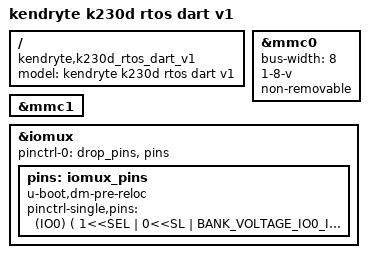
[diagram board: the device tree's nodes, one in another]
/dts-v1/;
#include <dt-bindings/pinctrl/k230-pinctrl.h>
#define BANK_VOLTAGE_IO0_IO1  K230_MSC_1V8
#define BANK_VOLTAGE_IO2_IO13 K230_MSC_3V3
#define BANK_VOLTAGE_IO14_IO25  K230_MSC_3V3
#define BANK_VOLTAGE_IO26_IO37  K230_MSC_3V3
#define BANK_VOLTAGE_IO38_IO49  K230_MSC_3V3
#define BANK_VOLTAGE_IO50_IO61  K230_MSC_3V3
#define BANK_VOLTAGE_IO62_IO63  K230_MSC_3V3
#include "k230d.dtsi"

/ {
    model = "kendryte k230d rtos dart v1";
    compatible = "kendryte,k230d_rtos_dart_v1";
};

&mmc0 {
    bus-width = <8>;
    1-8-v;
    non-removable;
    status = "okay";
};

&mmc1 {
    status = "okay";
};

&iomux {
    pinctrl-names = "default";
    pinctrl-0 = <&drop_pins &pins>;
//	Please pay attention to the bank voltage! will damage the chip.
    pins: iomux_pins {
        u-boot,dm-pre-reloc;
        pinctrl-single,pins = <
		(IO0) ( 1<<SEL | 0<<SL | BANK_VOLTAGE_IO0_IO1 <<MSC | 1<<IE | 0<<OE | 0<<PU | 0<<PD | 2<<DS | 1<<ST ) /* BOOT0 */
		(IO1) ( 1<<SEL | 0<<SL | BANK_VOLTAGE_IO0_IO1 <<MSC | 1<<IE | 0<<OE | 0<<PU | 0<<PD | 2<<DS | 1<<ST ) /* BOOT1 */
		(IO2) ( 0<<SEL | 0<<SL | BANK_VOLTAGE_IO2_IO13 <<MSC | 1<<IE | 1<<OE | 0<<PU | 0<<PD | 7<<DS | 1<<ST ) /* SC038HGS TRIG1: held low for free-running capture */
		(IO3) ( 0<<SEL | 0<<SL | BANK_VOLTAGE_IO2_IO13 <<MSC | 1<<IE | 1<<OE | 0<<PU | 0<<PD | 7<<DS | 1<<ST ) /* GPIO3 */
		(IO4) ( 0<<SEL | 0<<SL | BANK_VOLTAGE_IO2_IO13 <<MSC | 1<<IE | 1<<OE | 0<<PU | 0<<PD | 7<<DS | 1<<ST ) /* SC038HGS PWDN: low = off, high = enabled */
		(IO5) ( 0<<SEL | 0<<SL | BANK_VOLTAGE_IO2_IO13 <<MSC | 1<<IE | 1<<OE | 0<<PU | 0<<PD | 7<<DS | 1<<ST ) /* GPIO5 */
		(IO6) ( 0<<SEL | 0<<SL | BANK_VOLTAGE_IO2_IO13 <<MSC | 1<<IE | 1<<OE | 0<<PU | 0<<PD | 7<<DS | 1<<ST ) /* GPIO6 */
		(IO7) ( 1<<SEL | 0<<SL | BANK_VOLTAGE_IO2_IO13 <<MSC | 0<<IE | 1<<OE | 0<<PU | 1<<PD | 7<<DS | 0<<ST ) /* PWM2 */
		(IO8) ( 1<<SEL | 0<<SL | BANK_VOLTAGE_IO2_IO13 <<MSC | 0<<IE | 1<<OE | 0<<PU | 1<<PD | 7<<DS | 0<<ST ) /* PWM3 */
		(IO10) ( 0<<SEL | 0<<SL | BANK_VOLTAGE_IO2_IO13 <<MSC | 1<<IE | 1<<OE | 0<<PU | 0<<PD | 7<<DS | 1<<ST ) /* GPIO10 */
		(IO11) ( 3<<SEL | 0<<SL | BANK_VOLTAGE_IO2_IO13 <<MSC | 1<<IE | 1<<OE | 1<<PU | 0<<PD | 7<<DS | 1<<ST ) /* IIC2_SCL */
		(IO12) ( 3<<SEL | 0<<SL | BANK_VOLTAGE_IO2_IO13 <<MSC | 1<<IE | 1<<OE | 1<<PU | 0<<PD | 7<<DS | 1<<ST ) /* IIC2_SDA */
		(IO13) ( 0<<SEL | 0<<SL | BANK_VOLTAGE_IO2_IO13 <<MSC | 0<<IE | 0<<OE | 0<<PU | 0<<PD | 0<<DS | 0<<ST ) /* NC */
		(IO14) ( 3<<SEL | 0<<SL | BANK_VOLTAGE_IO14_IO25 <<MSC | 0<<IE | 1<<OE | 1<<PU | 0<<PD | 7<<DS | 0<<ST ) /* QSPI0_CS0 */
		(IO15) ( 3<<SEL | 0<<SL | BANK_VOLTAGE_IO14_IO25 <<MSC | 0<<IE | 1<<OE | 0<<PU | 0<<PD | 7<<DS | 0<<ST ) /* QSPI0_CLK */
		(IO16) ( 3<<SEL | 0<<SL | BANK_VOLTAGE_IO14_IO25 <<MSC | 0<<IE | 1<<OE | 0<<PU | 0<<PD | 7<<DS | 0<<ST ) /* QSPI0_D0 */
		(IO17) ( 3<<SEL | 0<<SL | BANK_VOLTAGE_IO14_IO25 <<MSC | 1<<IE | 0<<OE | 0<<PU | 0<<PD | 7<<DS | 1<<ST ) /* QSPI0_D1 */
		(IO18) ( 0<<SEL | 0<<SL | BANK_VOLTAGE_IO14_IO25 <<MSC | 1<<IE | 1<<OE | 0<<PU | 0<<PD | 7<<DS | 1<<ST ) /* GPIO18 */
		(IO19) ( 0<<SEL | 0<<SL | BANK_VOLTAGE_IO14_IO25 <<MSC | 1<<IE | 1<<OE | 0<<PU | 0<<PD | 7<<DS | 1<<ST ) /* GPIO19 */
		(IO20) ( 2<<SEL | 0<<SL | BANK_VOLTAGE_IO14_IO25 <<MSC | 0<<IE | 1<<OE | 1<<PU | 0<<PD | 7<<DS | 0<<ST ) /* QSPI1_CS0 */
		(IO21) ( 2<<SEL | 0<<SL | BANK_VOLTAGE_IO14_IO25 <<MSC | 0<<IE | 1<<OE | 0<<PU | 0<<PD | 7<<DS | 0<<ST ) /* QSPI1_CLK */
		(IO22) ( 2<<SEL | 0<<SL | BANK_VOLTAGE_IO14_IO25 <<MSC | 0<<IE | 1<<OE | 0<<PU | 0<<PD | 7<<DS | 0<<ST ) /* QSPI1_D0 */
		(IO23) ( 2<<SEL | 0<<SL | BANK_VOLTAGE_IO14_IO25 <<MSC | 1<<IE | 0<<OE | 0<<PU | 0<<PD | 7<<DS | 1<<ST ) /* QSPI1_D1 */
		(IO24) ( 0<<SEL | 0<<SL | BANK_VOLTAGE_IO14_IO25 <<MSC | 1<<IE | 1<<OE | 0<<PU | 0<<PD | 7<<DS | 1<<ST ) /* GPIO24 */
		(IO25) ( 0<<SEL | 0<<SL | BANK_VOLTAGE_IO14_IO25 <<MSC | 1<<IE | 1<<OE | 0<<PU | 0<<PD | 7<<DS | 1<<ST ) /* GPIO25 */
		(IO26) ( 1<<SEL | 0<<SL | BANK_VOLTAGE_IO26_IO37 <<MSC | 0<<IE | 1<<OE | 0<<PU | 0<<PD | 7<<DS | 0<<ST ) /* MMC1_CLK */
		(IO27) ( 1<<SEL | 0<<SL | BANK_VOLTAGE_IO26_IO37 <<MSC | 1<<IE | 1<<OE | 1<<PU | 0<<PD | 7<<DS | 1<<ST ) /* MMC1_CMD */
		(IO28) ( 1<<SEL | 0<<SL | BANK_VOLTAGE_IO26_IO37 <<MSC | 1<<IE | 1<<OE | 1<<PU | 0<<PD | 7<<DS | 1<<ST ) /* MMC1_D0 */
		(IO29) ( 1<<SEL | 0<<SL | BANK_VOLTAGE_IO26_IO37 <<MSC | 1<<IE | 1<<OE | 1<<PU | 0<<PD | 7<<DS | 1<<ST ) /* MMC1_D1 */
		(IO30) ( 1<<SEL | 0<<SL | BANK_VOLTAGE_IO26_IO37 <<MSC | 1<<IE | 1<<OE | 1<<PU | 0<<PD | 7<<DS | 1<<ST ) /* MMC1_D2 */
		(IO31) ( 1<<SEL | 0<<SL | BANK_VOLTAGE_IO26_IO37 <<MSC | 1<<IE | 1<<OE | 1<<PU | 0<<PD | 7<<DS | 1<<ST ) /* MMC1_D3 */
		(IO32) ( 3<<SEL | 0<<SL | BANK_VOLTAGE_IO26_IO37 <<MSC | 0<<IE | 1<<OE | 0<<PU | 0<<PD | 7<<DS | 0<<ST ) /* UART3_TXD */
		(IO33) ( 3<<SEL | 0<<SL | BANK_VOLTAGE_IO26_IO37 <<MSC | 1<<IE | 0<<OE | 0<<PU | 0<<PD | 7<<DS | 1<<ST ) /* UART3_RXD */
		(IO34) ( 1<<SEL | 0<<SL | BANK_VOLTAGE_IO26_IO37 <<MSC | 1<<IE | 1<<OE | 1<<PU | 0<<PD | 7<<DS | 1<<ST ) /* SC038HGS IIC1_SCL */
		(IO35) ( 1<<SEL | 0<<SL | BANK_VOLTAGE_IO26_IO37 <<MSC | 1<<IE | 1<<OE | 1<<PU | 0<<PD | 7<<DS | 1<<ST ) /* SC038HGS IIC1_SDA */
		(IO36) ( 1<<SEL | 0<<SL | BANK_VOLTAGE_IO26_IO37 <<MSC | 1<<IE | 1<<OE | 1<<PU | 0<<PD | 7<<DS | 1<<ST ) /* IIC3_SCL */
		(IO37) ( 1<<SEL | 0<<SL | BANK_VOLTAGE_IO26_IO37 <<MSC | 1<<IE | 1<<OE | 1<<PU | 0<<PD | 7<<DS | 1<<ST ) /* IIC3_SDA */
		(IO38) ( 1<<SEL | 0<<SL | BANK_VOLTAGE_IO38_IO49 <<MSC | 0<<IE | 1<<OE | 0<<PU | 0<<PD | 7<<DS | 0<<ST ) /* UART0_TXD */
		(IO39) ( 1<<SEL | 0<<SL | BANK_VOLTAGE_IO38_IO49 <<MSC | 1<<IE | 0<<OE | 0<<PU | 0<<PD | 7<<DS | 1<<ST ) /* UART0_RXD */
		(IO40) ( 1<<SEL | 0<<SL | BANK_VOLTAGE_IO38_IO49 <<MSC | 0<<IE | 1<<OE | 0<<PU | 0<<PD | 7<<DS | 0<<ST ) /* UART1_TXD */
		(IO41) ( 1<<SEL | 0<<SL | BANK_VOLTAGE_IO38_IO49 <<MSC | 1<<IE | 0<<OE | 0<<PU | 0<<PD | 7<<DS | 1<<ST ) /* UART1_RXD */
		(IO44) ( 1<<SEL | 0<<SL | BANK_VOLTAGE_IO38_IO49 <<MSC | 0<<IE | 1<<OE | 0<<PU | 0<<PD | 7<<DS | 0<<ST ) /* UART2_TXD */
		(IO45) ( 1<<SEL | 0<<SL | BANK_VOLTAGE_IO38_IO49 <<MSC | 1<<IE | 0<<OE | 0<<PU | 0<<PD | 7<<DS | 1<<ST ) /* UART2_RXD */
		(IO48) ( 1<<SEL | 0<<SL | BANK_VOLTAGE_IO38_IO49 <<MSC | 0<<IE | 1<<OE | 0<<PU | 0<<PD | 7<<DS | 0<<ST ) /* UART4_TXD */
		(IO49) ( 1<<SEL | 0<<SL | BANK_VOLTAGE_IO38_IO49 <<MSC | 1<<IE | 0<<OE | 0<<PU | 0<<PD | 7<<DS | 1<<ST ) /* UART4_RXD */
		(IO59) ( 3<<SEL | 0<<SL | BANK_VOLTAGE_IO50_IO61 <<MSC | 0<<IE | 1<<OE | 0<<PU | 1<<PD | 7<<DS | 0<<ST ) /* PWM5 */
		(IO60) ( 1<<SEL | 0<<SL | BANK_VOLTAGE_IO50_IO61 <<MSC | 0<<IE | 1<<OE | 0<<PU | 1<<PD | 7<<DS | 0<<ST ) /* PWM0 */
		(IO61) ( 1<<SEL | 0<<SL | BANK_VOLTAGE_IO50_IO61 <<MSC | 0<<IE | 1<<OE | 0<<PU | 1<<PD | 7<<DS | 0<<ST ) /* PWM1 */
		(IO62) ( 0<<SEL | 0<<SL | BANK_VOLTAGE_IO62_IO63 <<MSC | 0<<IE | 0<<OE | 0<<PU | 0<<PD | 0<<DS | 0<<ST ) /* NC */
		(IO63) ( 0<<SEL | 0<<SL | BANK_VOLTAGE_IO62_IO63 <<MSC | 0<<IE | 0<<OE | 0<<PU | 0<<PD | 0<<DS | 0<<ST ) /* NC */
		>;
};
};
